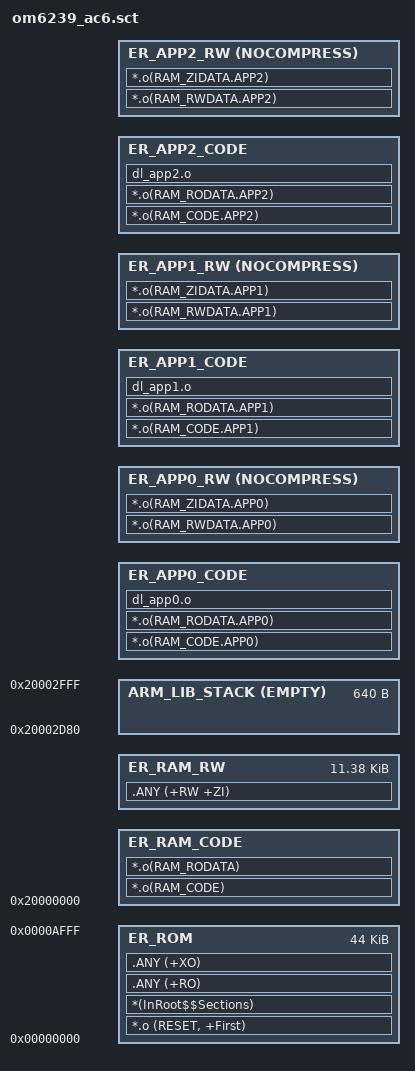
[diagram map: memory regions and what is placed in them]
#! armclang -E --target=arm-arm-none-eabi -mcpu=cortex-m0 -xc
; command above MUST be in first line (no comment above!)

/*
;-------- <<< Use Configuration Wizard in Context Menu >>> -------------------
*/

/*--------------------- Flash Configuration ----------------------------------
; <h> Flash Configuration
;   <o0> Flash Base Address <0x0-0xFFFFFFFF:8>
;   <o1> Flash Size (in Bytes) <0x0-0xFFFFFFFF:8>
; </h>
 *----------------------------------------------------------------------------*/
#define __RO_BASE      0x00000000
#define __RO_SIZE      0x0000B000               // 44K

/*--------------------- Embedded RAM Configuration ---------------------------
; <h> RAM Configuration
;   <o0> RAM Base Address    <0x0-0xFFFFFFFF:8>
;   <o1> RAM Size (in Bytes) <0x0-0xFFFFFFFF:8>
; </h>
 *----------------------------------------------------------------------------*/
#define __RAM_BASE      0x20000000
#define __RAM_SIZE      0x00003000

/*--------------------- Dynamic Load RAM0 Configuration ---------------------------
; <h> Dynamic Load RAM0 Configuration
;   <o0> RAM Base Address    <0x00200000-0x00202fff:8>
;   <o1> RAM Size (in Bytes) <0x0-0x00003000:8>
; </h>
 *----------------------------------------------------------------------------*/
#define __DL_RAM0_BASE      0x00200000
#define __DL_RAM0_SIZE      0x00003000

/*--------------------- Dynamic Load RAM1 Configuration ---------------------------
; <h> Dynamic Load RAM1 Configuration
;   <o0> RAM Base Address    <0x00204000-0x00206fff:8>
;   <o1> RAM Size (in Bytes) <0x0-0x00003000:8>
; </h>
 *----------------------------------------------------------------------------*/
#define __DL_RAM1_BASE      0x00204000
#define __DL_RAM1_SIZE      0x00003000

/*--------------------- Dynamic Load RAM2 Configuration ---------------------------
; <h> Dynamic Load RAM1 Configuration
;   <o0> RAM Base Address    <0x0020c000-0x0020efff:8>
;   <o1> RAM Size (in Bytes) <0x0-0x00003000:8>
; </h>
 *----------------------------------------------------------------------------*/
#define __DL_RAM2_BASE      0x0020c000
#define __DL_RAM2_SIZE      0x00003000

/*--------------------- Stack / Heap Configuration ---------------------------
; <h> Stack / Heap Configuration
;   <o0> Stack Size (in Bytes) <0x0-0xFFFFFFFF:8>
;   <o1> Heap Size (in Bytes) <0x0-0xFFFFFFFF:8>
; </h>
 *----------------------------------------------------------------------------*/
#define __STACK_SIZE    0x00000280
#define __HEAP_SIZE     0x00000000              // 没有使用自动分配内存功能大小改为0 2025-1-26 YQ

/*
;------------- <<< end of configuration section >>> ---------------------------
*/
/*----------------------------------------------------------------------------
  User Stack & Heap boundary definition
 *----------------------------------------------------------------------------*/
#define __STACK_TOP    (__RAM_BASE + __RAM_SIZE)    /* starts at end of RAM */
#define __HEAP_BASE    (AlignExpr(+0, 8))           /* starts after RW_RAM section, 8 byte aligned */


/*----------------------------------------------------------------------------
  Scatter File Definitions definition
 *----------------------------------------------------------------------------*/
#define __RW_BASE       __RAM_BASE
#define __RW_SIZE      (__RAM_SIZE - __STACK_SIZE - __HEAP_SIZE)


LR_ROM __RO_BASE   {                       ; load region size_region
  ER_ROM __RO_BASE __RO_SIZE  {                     ; load address = execution address
   *.o (RESET, +First)
   *(InRoot$$Sections)
   .ANY (+RO)
   .ANY (+XO)
  }

  ER_RAM_CODE __RW_BASE ALIGN 4 {
    *.o(RAM_CODE)
    *.o(RAM_RODATA)
  }

  ER_RAM_RW +0 __RW_SIZE  {                     ; RW data
   .ANY (+RW +ZI)
  }

#if __HEAP_SIZE > 0
  ARM_LIB_HEAP  __HEAP_BASE EMPTY  __HEAP_SIZE  {   ; Reserve empty region for heap
  }
#endif

  ARM_LIB_STACK __STACK_TOP EMPTY -__STACK_SIZE {   ; Reserve empty region for stack
  }

  ER_APP0_CODE __DL_RAM0_BASE+ImageLength(ER_RAM_CODE)+ImageLength(ER_RAM_RW){
    *.o(RAM_CODE.APP0)
    *.o(RAM_RODATA.APP0)
    dl_app0.o
  }

  ER_APP0_RW +0 NOCOMPRESS ALIGN 4 {
    *.o(RAM_RWDATA.APP0)
    *.o(RAM_ZIDATA.APP0)
  }

  ER_APP1_CODE __DL_RAM1_BASE+ImageLength(ER_RAM_CODE)+ImageLength(ER_RAM_RW){
    *.o(RAM_CODE.APP1)
    *.o(RAM_RODATA.APP1)
    dl_app1.o
  }

  ER_APP1_RW +0 NOCOMPRESS ALIGN 4 {
    *.o(RAM_RWDATA.APP1)
    *.o(RAM_ZIDATA.APP1)
  }

  ER_APP2_CODE __DL_RAM2_BASE+ImageLength(ER_RAM_CODE)+ImageLength(ER_RAM_RW){
    *.o(RAM_CODE.APP2)
    *.o(RAM_RODATA.APP2)
    dl_app2.o
  }

  ER_APP2_RW +0 NOCOMPRESS ALIGN 4 {
    *.o(RAM_RWDATA.APP2)
    *.o(RAM_ZIDATA.APP2)
  }
}
